# D1H register map
Vendor: Allwinner; File version: 1.0
Registers are 32-bit, read-write, reset 0x0 unless marked. A register's access mark holds for its fields unless they carry their own. Offsets are from the block's base; [hi:lo] are bit positions; {n}, {i} and the like mark numbered series; 'fields as' and 'values as' point back to an identical list.

## HSTimer — High Speed Timer
Base 0x03008000
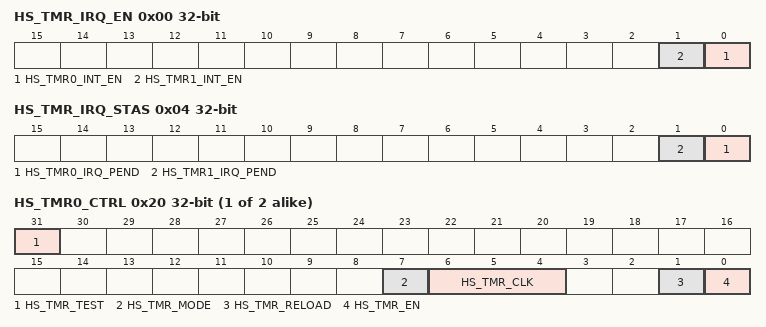
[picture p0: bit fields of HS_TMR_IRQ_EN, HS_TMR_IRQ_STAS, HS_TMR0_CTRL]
0x00 HS_TMR_IRQ_EN — HS Timer IRQ Enable Register
  [n] HS_TMR{n}_INT_EN (n=0..1) — HSTimer Interrupt Enable
    0=disabled; 1=enabled
0x04 HS_TMR_IRQ_STAS — HS Timer Status Register
  [n] HS_TMR{n}_IRQ_PEND (n=0..1) write-1-clears — HSTimer IRQ Pending
    0=no_effect; 1=pending
{0x20+0x20*i} HS_TMR{i}_CTRL (i=0..1) — HS Timer Control Register
  [31] HS_TMR_TEST — Select the operating mode for HSTimer
    0=Normal; 1=Test
  [7] HS_TMR_MODE — Select the timing mode for HSTimer
    0=periodic; 1=one_shot
  [6:4] HS_TMR_CLK — Select the pre-scale for the HSTimer clock sources
    0=P1; 1=P2; 2=P4; 3=P8; 4=P16
  [1] HS_TMR_RELOAD write-1-sets — HSTimer Reload
    0=no_effect; 1=reload
  [0] HS_TMR_EN — HSTimer Enable
    0=stop_pause; 1=start
{0x24+0x20*i} HS_TMR{i}_INTV_LO (i=0..1) — HS Timer Interval Value Low Register
{0x28+0x20*i} HS_TMR{i}_INTV_HI (i=0..1) — HS Timer Interval Value High Register
  [23:0] HS_TMR_INTV_VALUE_HI
{0x2C+0x20*i} HS_TMR{i}_CURNT_LO (i=0..1) — HS Timer Current Value Low Register
{0x30+0x20*i} HS_TMR{i}_CURNT_HI (i=0..1) — HS Timer Current Value High Register
  [23:0] HS_TMR_CUR_VALUE_HI

## PLIC — Platform Level Interrupt Control
Base 0x10000000
{0x0+4i} prio[{i}] (i=0..255) — Interrupt Priority Register
  [4:0] priority
    0=P0 (Priority 0 (never interrupt)); {v}=P{v} (Priority {v}) (v=1..31)
{0x1000+4i} ip[{i}] (i=0..8) — Interrupt Pending Register
{0x2000+4i} mie[{i}] (i=0..8) — Machine Mode Interrupt Enable Register
{0x2080+4i} sie[{i}] (i=0..8) — Supervisor Mode Interrupt Enable Register
0x1FFFFC ctrl — Control Register
  [0] ctrl — PLIC Control
    0=m (Only the machine mode can access to all registers in PLIC. Supervisor mode can only access the interrupt threshold register and the interrupt response/completion register.); 1=ms (The machine mode and the supervisor mode can access all registers. CTRL is accessible only in the machine mode.)
0x200000 mth — Machine Mode Priority Threshold Register
  fields as prio[0]
0x200004 mclaim — Machine Mode Claim/Complete Register
  [9:0] mclaim
0x201000 sth — Supervisor Mode Priority Threshold Register
  fields as prio[0]
0x201004 sclaim — Supervisor Mode Claim/Complete Register
  [9:0] sclaim

## DMAC — Direct Memory Access Controller
Base 0x03002000
0x00 DMAC_IRQ_EN_REG0 — DMAC IRQ Enable Register 0
0x04 DMAC_IRQ_EN_REG1 — DMAC IRQ Enable Register 1
0x10 DMAC_IRQ_PEND_REG0 — DMAC IRQ Pending Register 0
0x14 DMAC_IRQ_PEND_REG1 — DMAC IRQ Pending Register 1
0x28 DMAC_AUTO_GATE_REG — DMAC Auto Gating Register
0x30 DMAC_STA_REG — DMAC Status Register
{0x100+0x40*i} DMAC_EN_REG{i} (i=0..15) — DMAC Channel Enable Register
{0x104+0x40*i} DMAC_PAU_REG{i} (i=0..15) — DMAC Channel Pause Register
{0x108+0x40*i} DMAC_DESC_ADDR_REG{i} (i=0..15) — DMAC Channel Start Address Register
{0x10C+0x40*i} DMAC_CFG_REG{i} (i=0..15) — DMAC Channel Configuration Register
{0x110+0x40*i} DMAC_CUR_SRC_REG{i} (i=0..15) — DMAC Channel Current Source Register
{0x114+0x40*i} DMAC_CUR_DEST_REG{i} (i=0..15) — DMAC Channel Current Destination Register
{0x118+0x40*i} DMAC_BCNT_LEFT_REG{i} (i=0..15) — DMAC Channel Byte Counter Left Register
{0x11C+0x40*i} DMAC_PARA_REG{i} (i=0..15) — DMAC Channel Parameter Register
{0x128+0x40*i} DMAC_MODE_REG{i} (i=0..15) — DMAC Mode Register
{0x12C+0x40*i} DMAC_FDESC_ADDR_REG{i} (i=0..15) — DMAC Former Descriptor Address Register
{0x130+0x40*i} DMAC_PKG_NUM_REG{i} (i=0..15) — DMAC Package Number Register

## THC — Thermal Sensor Controller
Base 0x02009400
0x00 THS_CTRL — THS Control Register
0x04 THS_EN — THS Enable Register
0x08 THS_PER — THS Period Control Register
0x10 THS_DATA_INTC — THS Data Interrupt Control Register
0x14 THS_SHUT_INTC — THS Shut Interrupt Control Register
0x18 THS_ALARM_INTC — THS Alarm Interrupt Control Register
0x20 THS_DATA_INTS — THS Data Interrupt Status Register
0x24 THS_SHUT_INTS — THS Shut Interrupt Status Register
0x28 THS_ALARMO_INTS — THS Alarm off Interrupt Status Register
0x2C THS_ALARM_INTS — THS Alarm Interrupt Status Register
0x30 THS_FILTER — THS Median Filter Control Register
0x40 THS_ALARM_CTRL — THS Alarm Threshold Control Register
0x80 THS_SHUTDOWN_CTRL — THS Shutdown Threshold Control Register
0xA0 THS_CDATA — THS Calibration Data
0xC0 THS_DATA
